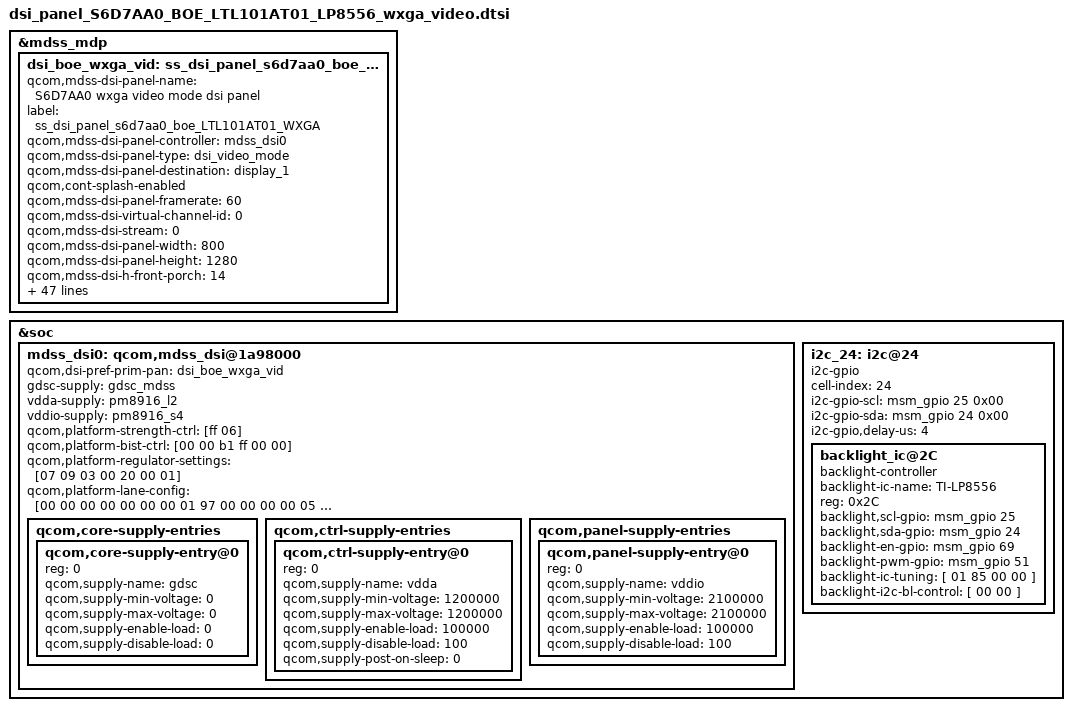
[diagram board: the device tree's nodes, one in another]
/* Copyright (c) 2013, The Linux Foundation. All rights reserved.
 *
 * This program is free software; you can redistribute it and/or modify
 * it under the terms of the GNU General Public License version 2 and
 * only version 2 as published by the Free Software Foundation.
 *
 * This program is distributed in the hope that it will be useful,
 * but WITHOUT ANY WARRANTY; without even the implied warranty of
 * MERCHANTABILITY or FITNESS FOR A PARTICULAR PURPOSE.  See the
 * GNU General Public License for more details.
 */

/*---------------------------------------------------------------------------
 * This file is autogenerated file using gcdb parser. Please do not edit it.
 * Update input XML file to add a new entry or update variable in this file
 * VERSION = "1.0"
 *---------------------------------------------------------------------------*/
&mdss_mdp {
	dsi_boe_wxga_vid: ss_dsi_panel_s6d7aa0_boe_LTL101AT01_WXGA {
		qcom,mdss-dsi-panel-name = "S6D7AA0 wxga video mode dsi panel";
		label = "ss_dsi_panel_s6d7aa0_boe_LTL101AT01_WXGA";
		qcom,mdss-dsi-panel-controller = <&mdss_dsi0>;
		qcom,mdss-dsi-panel-type = "dsi_video_mode";
		qcom,mdss-dsi-panel-destination = "display_1";
		qcom,cont-splash-enabled;
		qcom,mdss-dsi-panel-framerate = <60>;
		qcom,mdss-dsi-virtual-channel-id = <0>;
		qcom,mdss-dsi-stream = <0>;
		qcom,mdss-dsi-panel-width = <800>;
		qcom,mdss-dsi-panel-height = <1280>;
		qcom,mdss-dsi-h-front-porch = <14>;
		qcom,mdss-dsi-h-back-porch = <153>;
		qcom,mdss-dsi-h-pulse-width = <16>;
		qcom,mdss-dsi-h-sync-skew = <0>;
		qcom,mdss-dsi-v-back-porch = <4>;
		qcom,mdss-dsi-v-front-porch = <4>;
		qcom,mdss-dsi-v-pulse-width = <4>;
		qcom,mdss-dsi-h-left-border = <0>;
		qcom,mdss-dsi-h-right-border = <0>;
		qcom,mdss-dsi-v-top-border = <0>;
		qcom,mdss-dsi-v-bottom-border = <0>;
		qcom,mdss-dsi-bpp = <24>;
		qcom,mdss-dsi-underflow-color = <0xff>;
		qcom,mdss-dsi-border-color = <0>;
		qcom,mdss-dsi-on-command = [
			39 01 00 00 15 00 03 F0 5A 5A
			39 01 00 00 00 00 03 F1 5A 5A
			39 01 00 00 00 00 03 FC A5 A5
			39 01 00 00 00 00 03 D0 00 10
			39 01 00 00 15 00 03 B1 10 A0
			39 00 00 00 00 00 05 B2 14 22 2F 04
			39 00 00 00 00 00 05 D9 14 03 28 0A
			39 00 00 00 00 00 09 EE 00 00 0F 00 00 00 0F 00
			39 00 00 00 00 00 0B EF 56 56 43 43 90 80 04 80 00 00
			39 00 00 00 00 00 06 F2 03 08 08 9C 10
			39 00 00 00 00 00 0B F3 01 80 20 22 80 01 25 1C 00 71
			39 00 00 00 00 00 19 F4 02 02 10 26 10 02 03 03 03 10 16 03 00 0C 0C 03 04 05 13 1E 09 0A 05 05
			39 00 00 00 00 00 1B F5 62 1F 26 5F AB BB 75 0F 33 43 04 59 54 52 45 53 60 09 64 80 27 26 52 25 6A 1A
			39 00 00 00 00 00 07 F6 F0 24 86 00 00 18
			39 00 00 00 00 00 21 F7 10 1B 1A 0D 09 0C 08 04 01 01 01 01 01 01 01 01 11 1B 1A 0F 0B 0E 0A 05 01 01 01 01 01 01 01 01
			39 00 00 00 00 00 34 FA 10 3C 1C 23 25 18 1E 21 1F 22 22 22 23 1D 0D 08 0C 10 3C 1C 23 25 18 1E 21 1F 22 22 22 23 1D 0D 08 0C 10 3C 1C 23 25 18 1E 21 1F 22 22 22 23 1D 0D 08 0C
			39 00 00 00 00 00 34 FB 10 3C 1C 23 25 18 1E 21 1F 22 22 22 23 1D 0D 08 0C 10 3C 1C 23 25 18 1E 21 1F 22 22 22 23 1D 0D 08 0C 10 3C 1C 23 25 18 1E 21 1F 22 22 22 23 1D 0D 08 0C
			39 00 00 00 00 00 06 FD 16 10 11 20 09
			39 00 00 00 00 00 06 FE 00 02 03 21 80
			05 01 00 00 64 00 02 11 00
			05 01 00 00 01 00 02 29 00
		];
		qcom,mdss-dsi-off-command = [05 01 00 00 40 00 02 28 00
					05 01 00 00 0A 00 02 10 00
		];
		qcom,mdss-dsi-on-command-state = "dsi_lp_mode";
		qcom,mdss-dsi-off-command-state = "dsi_hs_mode";
		qcom,mdss-dsi-h-sync-pulse = <0>;
		qcom,mdss-dsi-bllp-eof-power-mode;
		qcom,mdss-dsi-bllp-power-mode;
		qcom,mdss-dsi-hbp-power-mode;
		qcom,mdss-dsi-lane-0-state;
		qcom,mdss-dsi-lane-1-state;
		qcom,mdss-dsi-lane-2-state;
		qcom,mdss-dsi-lane-3-state;
		qcom,mdss-dsi-panel-timings = [66 2B 0D 00 37 3D 12 2F 17 03 04 00];
		qcom,mdss-dsi-t-clk-post = <0x04>;
		qcom,mdss-dsi-t-clk-pre = <0x16>;
		qcom,mdss-dsi-bl-min-level = <1>;
		qcom,mdss-dsi-bl-max-level = <255>;
		qcom,mdss-dsi-dma-trigger = "trigger_sw";
		qcom,mdss-dsi-mdp-trigger = "none";
		qcom,mdss-dsi-bl-pmic-control-type = "bl_ctrl_ss_pwm";
		samsung,tft-common-support;
		samsung,backlight-gpio-config;
		samsung,backlight-pwm-ap-support;
		qcom,mdss-dsi-reset-sequence = <0 20>, <1 100>;
		qcom,mdss-pan-physical-width-dimension = <172>;
		qcom,mdss-pan-physical-height-dimension = <108>;
		qcom,mdss-dsi-lp11-init;
		qcom,mdss-dsi-init-delay-us = <20000>;
		qcom,mdss-dsi-force-clk-lane-hs;
		samsung,panel-vendor = "BOE";
	};
};
&soc {
	mdss_dsi0: qcom,mdss_dsi@1a98000 {
		qcom,dsi-pref-prim-pan = <&dsi_boe_wxga_vid>;
		gdsc-supply = <&gdsc_mdss>;
		vdda-supply = <&pm8916_l2>;
		vddio-supply = <&pm8916_s4>;
		qcom,platform-strength-ctrl = [ff 06];
		qcom,platform-bist-ctrl = [00 00 b1 ff 00 00];
		qcom,platform-regulator-settings = [07 09 03 00 20 00 01];
		qcom,platform-lane-config = [00 00 00 00 00 00 00 01 97
			00 00 00 00 05 00 00 01 97
			00 00 00 00 0a 00 00 01 97
			00 00 00 00 0f 00 00 01 97
			00 c0 00 00 00 00 00 01 bb];
		qcom,core-supply-entries {
			#address-cells = <1>;
			#size-cells = <0>;

			qcom,core-supply-entry@0 {
				reg = <0>;
				qcom,supply-name = "gdsc";
				qcom,supply-min-voltage = <0>;
				qcom,supply-max-voltage = <0>;
				qcom,supply-enable-load = <0>;
				qcom,supply-disable-load = <0>;
			};
		};
		qcom,ctrl-supply-entries {
			#address-cells = <1>;
			#size-cells = <0>;

			qcom,ctrl-supply-entry@0 {
				reg = <0>;
				qcom,supply-name = "vdda";
				qcom,supply-min-voltage = <1200000>;
				qcom,supply-max-voltage = <1200000>;
				qcom,supply-enable-load = <100000>;
				qcom,supply-disable-load = <100>;
				qcom,supply-post-on-sleep = <0>;
			};
		};
		qcom,panel-supply-entries {
			#address-cells = <1>;
			#size-cells = <0>;

			qcom,panel-supply-entry@0 {
				reg = <0>;
				qcom,supply-name = "vddio";
				qcom,supply-min-voltage = <2100000>;
				qcom,supply-max-voltage = <2100000>;
				qcom,supply-enable-load = <100000>;
				qcom,supply-disable-load = <100>;
			};
		};
	};
	i2c_24: i2c@24 {

		cell-index = <24>;
		compatible = "i2c-gpio";
		i2c-gpio-scl = <&msm_gpio 25  0x00>; /*scl gpio*/
		i2c-gpio-sda = <&msm_gpio 24 0x00>;  /*sda gpio*/
		i2c-gpio,delay-us = <4>;
		backlight_ic@2C {
			compatible = "backlight-controller";
			backlight-ic-name = "TI-LP8556";
			reg = <0x2C>;
			backlight,scl-gpio = <&msm_gpio 25 0x00>;
			backlight,sda-gpio = <&msm_gpio 24 0x00>;
			backlight-en-gpio = <&msm_gpio 69 0x00>;
			backlight-pwm-gpio = <&msm_gpio 51 0x00>;
			backlight-ic-tuning = [
					01	85
					00	00
			];
			backlight-i2c-bl-control = [
					00	00
			];
		};
	};
};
